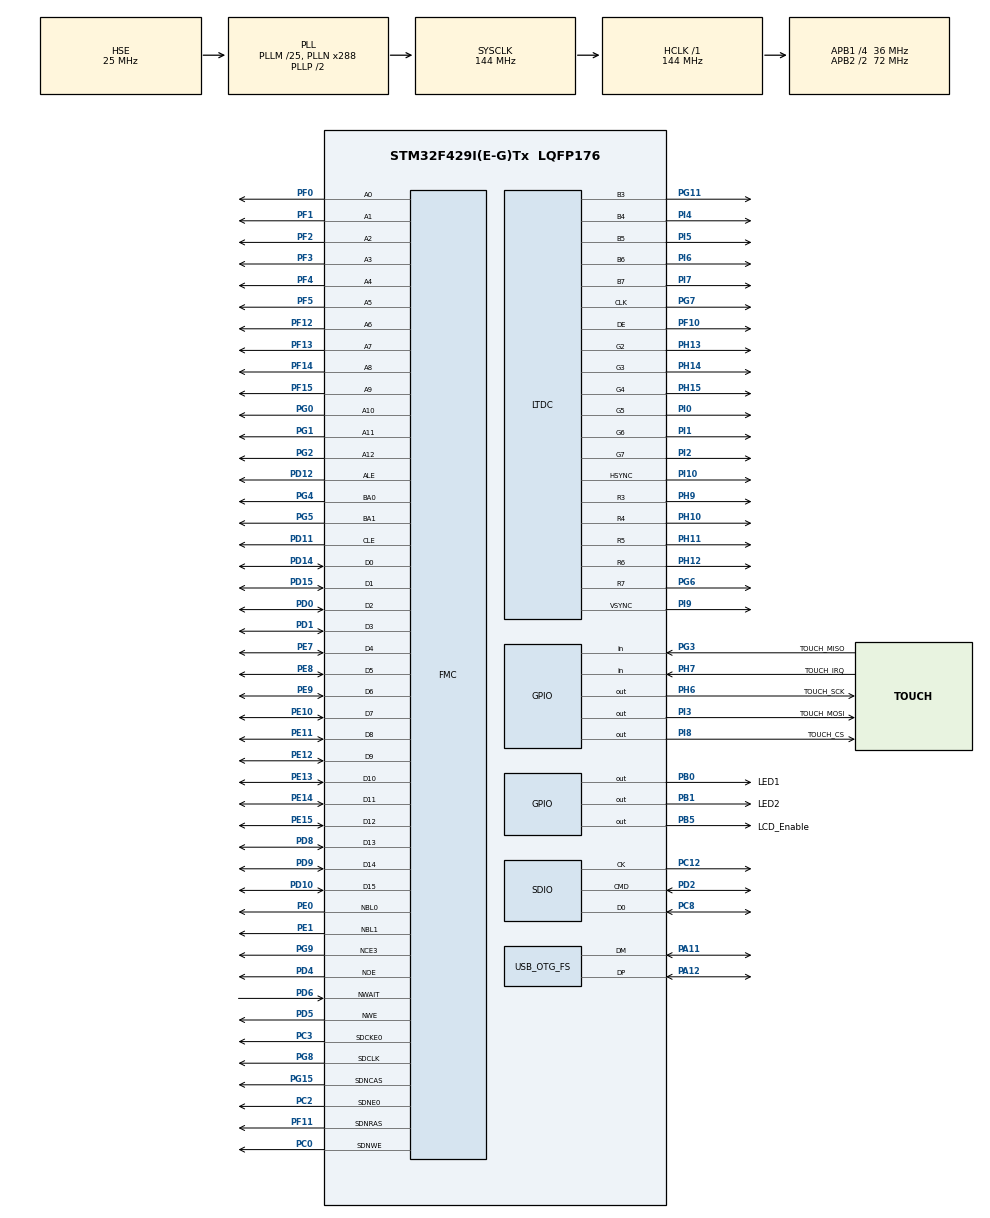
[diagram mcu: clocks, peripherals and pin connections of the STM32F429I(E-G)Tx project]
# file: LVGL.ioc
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DMA2D.ColorMode=DMA2D_OUTPUT_RGB565
FATFS._USE_LFN=2
FMC.AttributeSpaceHiZSetupTime1=252
FMC.AttributeSpaceHoldSetupTime1=10
FMC.AttributeSpaceSetupTime1=9
FMC.AttributeSpaceWaitSetupTime1=9
FMC.CASLatency1=FMC_SDRAM_CAS_LATENCY_2
FMC.ColumnBitsNumber1=FMC_SDRAM_COLUMN_BITS_NUM_9
FMC.CommonSpaceHiZSetupTime1=9
FMC.CommonSpaceHoldSetupTime1=10
FMC.CommonSpaceSetupTime1=9
FMC.CommonSpaceWaitSetupTime1=9
FMC.ExitSelfRefreshDelay1=7
FMC.LoadToActiveDelay1=2
FMC.NandBlockNbr1=2048
FMC.NandBlockSize1=64
FMC.NandPageSize1=2048
FMC.NandPlaneNbr1=2
FMC.NandPlaneSize1=1024
FMC.NandSpareAreaSize1=8
FMC.RCDDelay1=2
FMC.RPDelay1=2
FMC.RowCycleDelay1=7
FMC.SDClockPeriod1=FMC_SDRAM_CLOCK_PERIOD_2
FMC.SelfRefreshTime1=4
FMC.TARSetupTime1=1
FMC.TCLRSetupTime1=1
FMC.WriteRecoveryTime1=3
LTDC.ActiveW=800
LTDC.Alpha_L0=255
LTDC.FBStartAdress_L0=0xC0000000
LTDC.HBP=46
LTDC.HFP=210
LTDC.HSync=1
LTDC.ImageHeight_L0=480
LTDC.ImageWidth_L0=800
LTDC.Layers=0
LTDC.PixelFormat_L0=LTDC_PIXEL_FORMAT_RGB565
LTDC.VBP=23
LTDC.VFP=22
LTDC.VSync=1
LTDC.WindowX1_L0=800
LTDC.WindowY1_L0=480
Mcu.Family=STM32F4
Mcu.Name=STM32F429I(E-G)Tx
Mcu.Package=LQFP176
NVIC.DMA2D_IRQn=true\:0\:0\:false\:false\:true\:true\:true
NVIC.LTDC_IRQn=true\:0\:0\:false\:false\:true\:true\:true
NVIC.OTG_FS_IRQn=true\:0\:0\:false\:false\:true\:false\:true
NVIC.PriorityGroup=NVIC_PRIORITYGROUP_4
PA11.Mode=Device_Only
PA11.Signal=USB_OTG_FS_DM
PA12.Mode=Device_Only
PA12.Signal=USB_OTG_FS_DP
PA13.Mode=Serial_Wire
PA13.Signal=SYS_JTMS-SWDIO
PA14.Mode=Serial_Wire
PA14.Signal=SYS_JTCK-SWCLK
PB0.GPIO_Label=LED1
PB0.Signal=GPIO_Output
PB1.GPIO_Label=LED2
PB1.Signal=GPIO_Output
PB5.GPIO_Label=LCD_Enable
PB5.PinState=GPIO_PIN_SET
PB5.Signal=GPIO_Output
PC0.Signal=FMC_SDNWE
PC12.Mode=SD_1_bit
PC12.Signal=SDIO_CK
PC2.Mode=SdramChipSelect1_1
PC2.Signal=FMC_SDNE0
PC3.Mode=SdramChipSelect1_1
PC3.Signal=FMC_SDCKE0
PC8.Mode=SD_1_bit
PC8.Signal=SDIO_D0
PD0.Signal=FMC_D2_DA2
PD1.Signal=FMC_D3_DA3
PD10.Signal=FMC_D15_DA15
PD11.Signal=FMC_A16_CLE
PD12.Signal=FMC_A17_ALE
PD14.Signal=FMC_D0_DA0
PD15.Signal=FMC_D1_DA1
PD2.Mode=SD_1_bit
PD2.Signal=SDIO_CMD
PD4.Signal=FMC_NOE
PD5.Signal=FMC_NWE
PD6.Signal=FMC_NWAIT
PD8.Signal=FMC_D13_DA13
PD9.Signal=FMC_D14_DA14
PE0.Signal=FMC_NBL0
PE1.Signal=FMC_NBL1
PE10.Signal=FMC_D7_DA7
PE11.Signal=FMC_D8_DA8
PE12.Signal=FMC_D9_DA9
PE13.Signal=FMC_D10_DA10
PE14.Signal=FMC_D11_DA11
PE15.Signal=FMC_D12_DA12
PE7.Signal=FMC_D4_DA4
PE8.Signal=FMC_D5_DA5
PE9.Signal=FMC_D6_DA6
PF0.Signal=FMC_A0
PF1.Signal=FMC_A1
PF10.GPIO_Speed=GPIO_SPEED_FREQ_VERY_HIGH
PF10.Mode=RGB565
PF10.Signal=LTDC_DE
PF11.Signal=FMC_SDNRAS
PF12.Signal=FMC_A6
PF13.Signal=FMC_A7
PF14.Signal=FMC_A8
PF15.Signal=FMC_A9
PF2.Signal=FMC_A2
PF3.Signal=FMC_A3
PF4.Signal=FMC_A4
PF5.Signal=FMC_A5
PG0.Signal=FMC_A10
PG1.Signal=FMC_A11
PG11.GPIO_Speed=GPIO_SPEED_FREQ_VERY_HIGH
PG11.Mode=RGB565
PG11.Signal=LTDC_B3
PG15.Signal=FMC_SDNCAS
PG2.Signal=FMC_A12
PG3.GPIO_Label=TOUCH_MISO
PG3.Signal=GPIO_Input
PG4.Signal=FMC_A14_BA0
PG5.Signal=FMC_A15_BA1
PG6.GPIO_Speed=GPIO_SPEED_FREQ_VERY_HIGH
PG6.Mode=RGB565
PG6.Signal=LTDC_R7
PG7.GPIO_Speed=GPIO_SPEED_FREQ_VERY_HIGH
PG7.Mode=RGB565
PG7.Signal=LTDC_CLK
PG8.Signal=FMC_SDCLK
PG9.Mode=NandChipSelect3_1
PG9.Signal=FMC_NCE3
PH0/OSC_IN.Mode=HSE-External-Oscillator
PH0/OSC_IN.Signal=RCC_OSC_IN
PH1/OSC_OUT.Mode=HSE-External-Oscillator
PH1/OSC_OUT.Signal=RCC_OSC_OUT
PH10.GPIO_Speed=GPIO_SPEED_FREQ_VERY_HIGH
PH10.Mode=RGB565
PH10.Signal=LTDC_R4
PH11.GPIO_Speed=GPIO_SPEED_FREQ_VERY_HIGH
PH11.Mode=RGB565
PH11.Signal=LTDC_R5
PH12.GPIO_Speed=GPIO_SPEED_FREQ_VERY_HIGH
PH12.Mode=RGB565
PH12.Signal=LTDC_R6
PH13.GPIO_Speed=GPIO_SPEED_FREQ_VERY_HIGH
PH13.Mode=RGB565
PH13.Signal=LTDC_G2
PH14.GPIO_Speed=GPIO_SPEED_FREQ_VERY_HIGH
PH14.Mode=RGB565
PH14.Signal=LTDC_G3
PH15.GPIO_Speed=GPIO_SPEED_FREQ_VERY_HIGH
PH15.Mode=RGB565
PH15.Signal=LTDC_G4
PH6.GPIO_Label=TOUCH_SCK
PH6.Signal=GPIO_Output
PH7.GPIO_Label=TOUCH_IRQ
PH7.Signal=GPIO_Input
PH9.GPIO_Speed=GPIO_SPEED_FREQ_VERY_HIGH
PH9.Mode=RGB565
PH9.Signal=LTDC_R3
PI0.GPIO_Speed=GPIO_SPEED_FREQ_VERY_HIGH
PI0.Mode=RGB565
PI0.Signal=LTDC_G5
PI1.GPIO_Speed=GPIO_SPEED_FREQ_VERY_HIGH
PI1.Mode=RGB565
PI1.Signal=LTDC_G6
PI10.GPIO_Speed=GPIO_SPEED_FREQ_VERY_HIGH
PI10.Mode=RGB565
PI10.Signal=LTDC_HSYNC
PI2.GPIO_Speed=GPIO_SPEED_FREQ_VERY_HIGH
PI2.Mode=RGB565
PI2.Signal=LTDC_G7
PI3.GPIO_Label=TOUCH_MOSI
PI3.Signal=GPIO_Output
PI4.GPIO_Speed=GPIO_SPEED_FREQ_VERY_HIGH
PI4.Mode=RGB565
PI4.Signal=LTDC_B4
PI5.GPIO_Speed=GPIO_SPEED_FREQ_VERY_HIGH
PI5.Mode=RGB565
PI5.Signal=LTDC_B5
PI6.GPIO_Speed=GPIO_SPEED_FREQ_VERY_HIGH
PI6.Mode=RGB565
PI6.Signal=LTDC_B6
PI7.GPIO_Speed=GPIO_SPEED_FREQ_VERY_HIGH
PI7.Mode=RGB565
PI7.Signal=LTDC_B7
PI8.GPIO_Label=TOUCH_CS
PI8.Signal=GPIO_Output
PI9.GPIO_Speed=GPIO_SPEED_FREQ_VERY_HIGH
PI9.Mode=RGB565
PI9.Signal=LTDC_VSYNC
ProjectManager.HeapSize=0x2000
ProjectManager.StackSize=0x2000
ProjectManager.TargetToolchain=MDK-ARM V5.27
RCC.48MHZClocksFreq_Value=48000000
RCC.AHBFreq_Value=144000000
RCC.APB1CLKDivider=RCC_HCLK_DIV4
RCC.APB1Freq_Value=36000000
RCC.APB1TimFreq_Value=72000000
RCC.APB2CLKDivider=RCC_HCLK_DIV2
RCC.APB2Freq_Value=72000000
RCC.APB2TimFreq_Value=144000000
RCC.CortexFreq_Value=144000000
RCC.EnbaleCSS=true
RCC.HCLKFreq_Value=144000000
RCC.HSE_VALUE=25000000
RCC.HSI_VALUE=16000000
RCC.LSE_VALUE=32768
RCC.PLLM=25
RCC.PLLN=288
RCC.PLLQ=6
RCC.PLLSAIN=200
RCC.PLLSAIR=3
RCC.SYSCLKFreq_VALUE=144000000
RCC.SYSCLKSource=RCC_SYSCLKSOURCE_PLLCLK
RCC.VCOOutputFreq_Value=288000000
SH.FMC_A0.0=FMC_A0,13b-sda1
SH.FMC_A1.0=FMC_A1,13b-sda1
SH.FMC_A10.0=FMC_A10,13b-sda1
SH.FMC_A11.0=FMC_A11,13b-sda1
SH.FMC_A12.0=FMC_A12,13b-sda1
SH.FMC_A14_BA0.0=FMC_BA0,FourSdramBanks1
SH.FMC_A15_BA1.0=FMC_BA1,FourSdramBanks1
SH.FMC_A16_CLE.0=FMC_CLE,8b-dmux1
SH.FMC_A17_ALE.0=FMC_ALE,8b-dmux1
SH.FMC_A2.0=FMC_A2,13b-sda1
SH.FMC_A3.0=FMC_A3,13b-sda1
SH.FMC_A4.0=FMC_A4,13b-sda1
SH.FMC_A5.0=FMC_A5,13b-sda1
SH.FMC_A6.0=FMC_A6,13b-sda1
SH.FMC_A7.0=FMC_A7,13b-sda1
SH.FMC_A8.0=FMC_A8,13b-sda1
SH.FMC_A9.0=FMC_A9,13b-sda1
SH.FMC_D0_DA0.0=FMC_D0,sd-16b-d1
SH.FMC_D0_DA0.1=FMC_D0,8b-dmux1
SH.FMC_D10_DA10.0=FMC_D10,sd-16b-d1
SH.FMC_D11_DA11.0=FMC_D11,sd-16b-d1
SH.FMC_D12_DA12.0=FMC_D12,sd-16b-d1
SH.FMC_D13_DA13.0=FMC_D13,sd-16b-d1
SH.FMC_D14_DA14.0=FMC_D14,sd-16b-d1
SH.FMC_D15_DA15.0=FMC_D15,sd-16b-d1
SH.FMC_D1_DA1.0=FMC_D1,sd-16b-d1
SH.FMC_D1_DA1.1=FMC_D1,8b-dmux1
SH.FMC_D2_DA2.0=FMC_D2,sd-16b-d1
SH.FMC_D2_DA2.1=FMC_D2,8b-dmux1
SH.FMC_D3_DA3.0=FMC_D3,sd-16b-d1
SH.FMC_D3_DA3.1=FMC_D3,8b-dmux1
SH.FMC_D4_DA4.0=FMC_D4,sd-16b-d1
SH.FMC_D4_DA4.1=FMC_D4,8b-dmux1
SH.FMC_D5_DA5.0=FMC_D5,sd-16b-d1
SH.FMC_D5_DA5.1=FMC_D5,8b-dmux1
SH.FMC_D6_DA6.0=FMC_D6,sd-16b-d1
SH.FMC_D6_DA6.1=FMC_D6,8b-dmux1
SH.FMC_D7_DA7.0=FMC_D7,sd-16b-d1
SH.FMC_D7_DA7.1=FMC_D7,8b-dmux1
SH.FMC_D8_DA8.0=FMC_D8,sd-16b-d1
SH.FMC_D9_DA9.0=FMC_D9,sd-16b-d1
SH.FMC_NBL0.0=FMC_NBL0,Sd2ByteEnable1
SH.FMC_NBL1.0=FMC_NBL1,Sd2ByteEnable1
SH.FMC_NOE.0=FMC_NOE,8b-dmux1
SH.FMC_NWAIT.0=FMC_NWAIT,Wait1
SH.FMC_NWE.0=FMC_NWE,8b-dmux1
SH.FMC_SDCLK.0=FMC_SDCLK,13b-sda1
SH.FMC_SDNCAS.0=FMC_SDNCAS,13b-sda1
SH.FMC_SDNRAS.0=FMC_SDNRAS,13b-sda1
SH.FMC_SDNWE.0=FMC_SDNWE,13b-sda1
USB_DEVICE.CLASS_NAME_FS=CDC
USB_DEVICE.VirtualMode-CDC_FS=Cdc
USB_DEVICE.VirtualModeFS=Cdc_FS
USB_OTG_FS.VirtualMode=Device_Only
VP_CRC_VS_CRC.Mode=CRC_Activate
VP_DMA2D_VS_DMA2D.Mode=DMA2D_Activate
VP_FATFS_VS_SDIO.Mode=SDIO
VP_USB_DEVICE_VS_USB_DEVICE_CDC_FS.Mode=CDC_FS
board=custom

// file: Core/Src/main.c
/* USER CODE BEGIN Header */
/**
  ******************************************************************************
  * @file           : main.c
  * @brief          : Main program body
  ******************************************************************************
  * @attention
  *
  * <h2><center>&copy; Copyright (c) 2020 STMicroelectronics.
  * All rights reserved.</center></h2>
  *
  * This software component is licensed by ST under Ultimate Liberty license
  * SLA0044, the "License"; You may not use this file except in compliance with
  * the License. You may obtain a copy of the License at:
  *                             www.st.com/SLA0044
  *
  ******************************************************************************
  */
/* USER CODE END Header */
#include "main.h"
#include "fatfs.h"
#include "usb_device.h"

/* USER CODE BEGIN Includes */
#include "usbd_cdc_if.h"
#include "../../lvgl/lvgl.h"
#include "../../lvgl/src/lv_init.h"
#include "../../lvgl/examples/lv_examples.h"

/* USER CODE END Includes */

/* USER CODE BEGIN PD */
#define WRITE_READ_ADDR   ((uint16_t*)0xC0000000)
#define SDRAM_MODEREG_BURST_LENGTH_1             ((uint16_t)0x0000)
#define SDRAM_MODEREG_BURST_LENGTH_2             ((uint16_t)0x0001)
#define SDRAM_MODEREG_BURST_LENGTH_4             ((uint16_t)0x0002)
#define SDRAM_MODEREG_BURST_LENGTH_8             ((uint16_t)0x0004)
#define SDRAM_MODEREG_BURST_TYPE_SEQUENTIAL      ((uint16_t)0x0000)
#define SDRAM_MODEREG_BURST_TYPE_INTERLEAVED     ((uint16_t)0x0008)
#define SDRAM_MODEREG_CAS_LATENCY_2              ((uint16_t)0x0020)
#define SDRAM_MODEREG_CAS_LATENCY_3              ((uint16_t)0x0030)
#define SDRAM_MODEREG_OPERATING_MODE_STANDARD    ((uint16_t)0x0000)
#define SDRAM_MODEREG_WRITEBURST_MODE_PROGRAMMED ((uint16_t)0x0000)
#define SDRAM_MODEREG_WRITEBURST_MODE_SINGLE     ((uint16_t)0x0200)
#define REFRESH_COUNT       ((uint32_t)1835)   /* SDRAM refresh counter (90MHz SD clock) */

#define LV_HOR_RES_MAX 800
#define LV_VER_RES_MAX 400

/* USER CODE END PD */

CRC_HandleTypeDef hcrc;

DMA2D_HandleTypeDef hdma2d;

LTDC_HandleTypeDef hltdc;

SD_HandleTypeDef hsd;

NAND_HandleTypeDef hnand1;
SDRAM_HandleTypeDef hsdram1;

/* USER CODE BEGIN PV */
/*A static or global variable to store the buffers*/
//lv_disp_t * disp;
//static lv_disp_buf_t disp_buf;
//static lv_disp_drv_t disp_drv;
//
///*Static or global buffer(s). The second buffer is optional*/
//static lv_color_t buf_1[LV_HOR_RES_MAX * 10];
//static lv_color_t buf_2[LV_HOR_RES_MAX * 10];

static uint16_t buf[LV_HOR_RES_MAX * LV_VER_RES_MAX / 10];

uint16_t* LCD_FB=(uint16_t*)0xC0000000; // LCD FRAME Buffer
NAND_AddressTypeDef NAND_Address;
static volatile uint32_t t_saved = 0;
/* USER CODE END PV */

void SystemClock_Config(void);
static void MX_GPIO_Init(void);
static void MX_LTDC_Init(void);
static void MX_FMC_Init(void);
static void MX_SDIO_SD_Init(void);
static void MX_DMA2D_Init(void);
static void MX_CRC_Init(void);
///* USER CODE BEGIN PFP */
//void lcd_flush_cb(lv_disp_drv_t * disp_drv, const lv_area_t * area, lv_color_t * color_p);
//void my_gpu_fill_cb(lv_disp_drv_t * disp_drv, lv_color_t * dest_buf, const lv_area_t * dest_area, const lv_area_t * fill_area, lv_color_t color);
void SDRAM_Initialization_Sequence(SDRAM_HandleTypeDef *hsdram, FMC_SDRAM_CommandTypeDef *Command);
//void monitor_cb(lv_disp_drv_t * d, uint32_t t, uint32_t p);
//static void tft_lcd_flush_cb(lv_disp_drv_t * drv, const lv_area_t * area, lv_color_t * color_p) ;

/* USER CODE END PFP */

/* USER CODE BEGIN 0 */

void HAL_SYSTICK_Callback(void)
{

}

void put_px(int32_t x, int32_t y, uint16_t color) {
    // This is a placeholder implementation. Replace it with your actual implementation
    // Write the pixel color to the display buffer at the specified coordinates
	buf[y * LV_HOR_RES_MAX + x] = lv_color_to_u32(lv_color_make((color >> 11) & 0x1F, (color >> 5) & 0x3F, color & 0x1F));
}

void my_flush_cb(lv_display_t * display, const lv_area_t * area, void * px_map)
{
    /*The most simple case (but also the slowest) to put all pixels to the screen one-by-one
     *`put_px` is just an example, it needs to be implemented by you.*/
    uint16_t * buf16 = (uint16_t *)px_map; /*Let's say it's a 16 bit (RGB565) display*/
    int32_t x, y;
    for(y = area->y1; y <= area->y2; y++) {
        for(x = area->x1; x <= area->x2; x++) {
            put_px(x, y, *buf16);
            buf16++;
        }
    }

    /* IMPORTANT!!!
     * Inform LVGL that you are ready with the flushing and buf is not used anymore*/
    lv_display_flush_ready(display);
}
//
//void my_flush_cb(lv_display_t * display, const lv_area_t *area, lv_color_t *color_p) {
//    // Handle the spinner (if needed)
//    // For example, update the spinner's animation here
//    // Draw other display content (similar to the previous implementation)
//    int32_t x, y;
//    for (y = area->y1; y <= area->y2; y++) {
//        for (x = area->x1; x <= area->x2; x++) {
//            // Replace the following line with your actual display driver function
//            // to set the pixel at coordinates (x, y) with the specified color
//            put_px(x, y, *color_p);
//            color_p++;
//        }
//    }
//
//}

/* USER CODE END 0 */

int main(void)
{
  /* USER CODE BEGIN 1 */
//	NAND_IDTypeDef NAND1_ID;
//	char buff[50],buff_len;
  /* USER CODE END 1 */

  /* MCU Configuration--------------------------------------------------------*/

  /* Reset of all peripherals, Initializes the Flash interface and the Systick. */
  HAL_Init();

  /* Configure the system clock */
  SystemClock_Config();

  /* Initialize all configured peripherals */
  MX_GPIO_Init();
  MX_LTDC_Init();
  MX_FMC_Init();
  MX_SDIO_SD_Init();
  MX_FATFS_Init();
  MX_DMA2D_Init();
  MX_CRC_Init();
  MX_USB_DEVICE_Init();
  /* USER CODE BEGIN 2 */
//  for (unsigned int l_ind=0; l_ind<=384000; l_ind++)
//	LCD_FB[l_ind]=0x0000;
//  HAL_Delay(2000);
//	HAL_NAND_Erase_Block(&hnand1,&NAND_Address);
//  HAL_NAND_Write_Page_8b(&hnand1,&NAND_Address,(uint8_t *)"21AH\n\r",1);
//  HAL_NAND_Read_ID(&hnand1,&NAND1_ID);
//  buff_len=sprintf(buff,"%d,%d,%d,%d\n\r",NAND1_ID.Device_Id,NAND1_ID.Maker_Id,NAND1_ID.Third_Id,NAND1_ID.Fourth_Id);
//  HAL_Delay(2000);
//  CDC_Transmit_FS((uint8_t*)buff,buff_len);
//	//	HAL_NAND_Read_Page_8b(&hnand1,&NAND_Address,(uint8_t *)buff2,1);
//  for (unsigned int l_ind=0; l_ind<=384000; l_ind++)
//	LCD_FB[l_ind]=0xDCBA;
//	/*Initialize `disp_buf` with the buffer(s) */
//  HAL_Delay(100);
  lv_init();
  /*Initialize `disp_buf` with the buffer(s) */
  lv_display_t *display = lv_display_create(LV_HOR_RES_MAX, LV_VER_RES_MAX);
  lv_display_set_buffers(display, buf, NULL, sizeof(buf),LV_DISPLAY_RENDER_MODE_PARTIAL);
  lv_display_set_flush_cb(display, my_flush_cb);

  lv_obj_t *parent = lv_obj_create(lv_scr_act());
  lv_obj_set_size(parent, 100, 80);
  lv_obj_set_style_bg_color(parent, lv_color_hex(0x003a57), LV_PART_MAIN);

  lv_obj_t *spinner = lv_spinner_create(parent);
  lv_spinner_set_anim_params(spinner, 1000, 45); // Customize spin duration and arc length
  lv_obj_align(spinner, LV_ALIGN_BOTTOM_MID, 0, 0);

//  lv_area_t rect_area = {10, 10, 50, 30};
//  uint16_t rect_color = 0xF800; // Red (RGB565)
//  draw_filled_rectangle(display, &rect_area, rect_color);

  /* USER CODE END 2 */

  /* Infinite loop */
  /* USER CODE BEGIN WHILE */
  while (1)
  {
	  HAL_Delay(10);
	  lv_tick_inc(10);
	  lv_task_handler();
    /* USER CODE END WHILE */

  }
}

void SystemClock_Config(void)
{
  RCC_OscInitTypeDef RCC_OscInitStruct = {0};
  RCC_ClkInitTypeDef RCC_ClkInitStruct = {0};
  RCC_PeriphCLKInitTypeDef PeriphClkInitStruct = {0};

  /** Configure the main internal regulator output voltage
  */
  __HAL_RCC_PWR_CLK_ENABLE();
  __HAL_PWR_VOLTAGESCALING_CONFIG(PWR_REGULATOR_VOLTAGE_SCALE1);
  /** Initializes the RCC Oscillators according to the specified parameters
  * in the RCC_OscInitTypeDef structure.
  */
  RCC_OscInitStruct.OscillatorType = RCC_OSCILLATORTYPE_HSE;
  RCC_OscInitStruct.HSEState = RCC_HSE_ON;
  RCC_OscInitStruct.PLL.PLLState = RCC_PLL_ON;
  RCC_OscInitStruct.PLL.PLLSource = RCC_PLLSOURCE_HSE;
  RCC_OscInitStruct.PLL.PLLM = 25;
  RCC_OscInitStruct.PLL.PLLN = 288;
  RCC_OscInitStruct.PLL.PLLP = RCC_PLLP_DIV2;
  RCC_OscInitStruct.PLL.PLLQ = 6;
  if (HAL_RCC_OscConfig(&RCC_OscInitStruct) != HAL_OK)
  {
    Error_Handler();
  }
  /** Initializes the CPU, AHB and APB buses clocks
  */
  RCC_ClkInitStruct.ClockType = RCC_CLOCKTYPE_HCLK|RCC_CLOCKTYPE_SYSCLK
                              |RCC_CLOCKTYPE_PCLK1|RCC_CLOCKTYPE_PCLK2;
  RCC_ClkInitStruct.SYSCLKSource = RCC_SYSCLKSOURCE_PLLCLK;
  RCC_ClkInitStruct.AHBCLKDivider = RCC_SYSCLK_DIV1;
  RCC_ClkInitStruct.APB1CLKDivider = RCC_HCLK_DIV4;
  RCC_ClkInitStruct.APB2CLKDivider = RCC_HCLK_DIV2;

  if (HAL_RCC_ClockConfig(&RCC_ClkInitStruct, FLASH_LATENCY_4) != HAL_OK)
  {
    Error_Handler();
  }
  PeriphClkInitStruct.PeriphClockSelection = RCC_PERIPHCLK_LTDC;
  PeriphClkInitStruct.PLLSAI.PLLSAIN = 200;
  PeriphClkInitStruct.PLLSAI.PLLSAIR = 3;
  PeriphClkInitStruct.PLLSAIDivR = RCC_PLLSAIDIVR_2;
  if (HAL_RCCEx_PeriphCLKConfig(&PeriphClkInitStruct) != HAL_OK)
  {
    Error_Handler();
  }
  /** Enables the Clock Security System
  */
  HAL_RCC_EnableCSS();
}

///**
//  * @brief CRC Initialization Function
//  * @param None
//  * @retval None
//  */
static void MX_CRC_Init(void)
{

  hcrc.Instance = CRC;
  if (HAL_CRC_Init(&hcrc) != HAL_OK)
  {
    Error_Handler();
  }

}

static void MX_DMA2D_Init(void)
{

  hdma2d.Instance = DMA2D;
  hdma2d.Init.Mode = DMA2D_M2M;
  hdma2d.Init.ColorMode = DMA2D_OUTPUT_RGB565;
  hdma2d.Init.OutputOffset = 0;
  hdma2d.LayerCfg[1].InputOffset = 0;
  hdma2d.LayerCfg[1].InputColorMode = DMA2D_INPUT_RGB565;
  hdma2d.LayerCfg[1].AlphaMode = DMA2D_NO_MODIF_ALPHA;
  hdma2d.LayerCfg[1].InputAlpha = 0;
  if (HAL_DMA2D_Init(&hdma2d) != HAL_OK)
  {
    Error_Handler();
  }
  if (HAL_DMA2D_ConfigLayer(&hdma2d, 1) != HAL_OK)
  {
    Error_Handler();
  }

}

///**
//  * @brief LTDC Initialization Function
//  * @param None
//  * @retval None
//  */
static void MX_LTDC_Init(void)
{

  LTDC_LayerCfgTypeDef pLayerCfg = {0};
  LTDC_LayerCfgTypeDef pLayerCfg1 = {0};

  hltdc.Instance = LTDC;
  hltdc.Init.HSPolarity = LTDC_HSPOLARITY_AL;
  hltdc.Init.VSPolarity = LTDC_VSPOLARITY_AL;
  hltdc.Init.DEPolarity = LTDC_DEPOLARITY_AL;
  hltdc.Init.PCPolarity = LTDC_PCPOLARITY_IPC;
  hltdc.Init.HorizontalSync = 0;
  hltdc.Init.VerticalSync = 0;
  hltdc.Init.AccumulatedHBP = 46;
  hltdc.Init.AccumulatedVBP = 23;
  hltdc.Init.AccumulatedActiveW = 846;
  hltdc.Init.AccumulatedActiveH = 503;
  hltdc.Init.TotalWidth = 1056;
  hltdc.Init.TotalHeigh = 525;
  hltdc.Init.Backcolor.Blue = 0;
  hltdc.Init.Backcolor.Green = 0;
  hltdc.Init.Backcolor.Red = 0;
  if (HAL_LTDC_Init(&hltdc) != HAL_OK)
  {
    Error_Handler();
  }
  pLayerCfg.WindowX0 = 0;
  pLayerCfg.WindowX1 = 800;
  pLayerCfg.WindowY0 = 0;
  pLayerCfg.WindowY1 = 480;
  pLayerCfg.PixelFormat = LTDC_PIXEL_FORMAT_RGB565;
  pLayerCfg.Alpha = 255;
  pLayerCfg.Alpha0 = 0;
  pLayerCfg.BlendingFactor1 = LTDC_BLENDING_FACTOR1_CA;
  pLayerCfg.BlendingFactor2 = LTDC_BLENDING_FACTOR2_CA;
  pLayerCfg.FBStartAdress = 0xC0000000;
  pLayerCfg.ImageWidth = 800;
  pLayerCfg.ImageHeight = 480;
  pLayerCfg.Backcolor.Blue = 0;
  pLayerCfg.Backcolor.Green = 0;
  pLayerCfg.Backcolor.Red = 0;
  if (HAL_LTDC_ConfigLayer(&hltdc, &pLayerCfg, 0) != HAL_OK)
  {
    Error_Handler();
  }
  pLayerCfg1.WindowX0 = 0;
  pLayerCfg1.WindowX1 = 0;
  pLayerCfg1.WindowY0 = 0;
  pLayerCfg1.WindowY1 = 0;
  pLayerCfg1.Alpha = 0;
  pLayerCfg1.Alpha0 = 0;
  pLayerCfg1.BlendingFactor1 = LTDC_BLENDING_FACTOR1_CA;
  pLayerCfg1.BlendingFactor2 = LTDC_BLENDING_FACTOR2_CA;
  pLayerCfg1.FBStartAdress = 0;
  pLayerCfg1.ImageWidth = 0;
  pLayerCfg1.ImageHeight = 0;
  pLayerCfg1.Backcolor.Blue = 0;
  pLayerCfg1.Backcolor.Green = 0;
  pLayerCfg1.Backcolor.Red = 0;
  if (HAL_LTDC_ConfigLayer(&hltdc, &pLayerCfg1, 1) != HAL_OK)
  {
    Error_Handler();
  }

}

///**
//  * @brief SDIO Initialization Function
//  * @param None
//  * @retval None
//  */
static void MX_SDIO_SD_Init(void)
{

  hsd.Instance = SDIO;
  hsd.Init.ClockEdge = SDIO_CLOCK_EDGE_RISING;
  hsd.Init.ClockBypass = SDIO_CLOCK_BYPASS_DISABLE;
  hsd.Init.ClockPowerSave = SDIO_CLOCK_POWER_SAVE_DISABLE;
  hsd.Init.BusWide = SDIO_BUS_WIDE_1B;
  hsd.Init.HardwareFlowControl = SDIO_HARDWARE_FLOW_CONTROL_DISABLE;
  hsd.Init.ClockDiv = 0;

}

/* FMC initialization function */
static void MX_FMC_Init(void)
{

  FMC_NAND_PCC_TimingTypeDef ComSpaceTiming = {0};
  FMC_NAND_PCC_TimingTypeDef AttSpaceTiming = {0};
  FMC_SDRAM_TimingTypeDef SdramTiming = {0};

  /** Perform the NAND1 memory initialization sequence
  */
  hnand1.Instance = FMC_NAND_DEVICE;
  /* hnand1.Init */
  hnand1.Init.NandBank = FMC_NAND_BANK3;
  hnand1.Init.Waitfeature = FMC_NAND_PCC_WAIT_FEATURE_ENABLE;
  hnand1.Init.MemoryDataWidth = FMC_NAND_PCC_MEM_BUS_WIDTH_8;
  hnand1.Init.EccComputation = FMC_NAND_ECC_DISABLE;
  hnand1.Init.ECCPageSize = FMC_NAND_ECC_PAGE_SIZE_256BYTE;
  hnand1.Init.TCLRSetupTime = 1;
  hnand1.Init.TARSetupTime = 1;
  /* hnand1.Config */
  hnand1.Config.PageSize = 2048;
  hnand1.Config.SpareAreaSize = 8;
  hnand1.Config.BlockSize = 64;
  hnand1.Config.BlockNbr = 2048;
  hnand1.Config.PlaneNbr = 2;
  hnand1.Config.PlaneSize = 1024;
  hnand1.Config.ExtraCommandEnable = DISABLE;
  /* ComSpaceTiming */
  ComSpaceTiming.SetupTime = 9;
  ComSpaceTiming.WaitSetupTime = 9;
  ComSpaceTiming.HoldSetupTime = 10;
  ComSpaceTiming.HiZSetupTime = 9;
  /* AttSpaceTiming */
  AttSpaceTiming.SetupTime = 9;
  AttSpaceTiming.WaitSetupTime = 9;
  AttSpaceTiming.HoldSetupTime = 10;
  AttSpaceTiming.HiZSetupTime = 252;

  if (HAL_NAND_Init(&hnand1, &ComSpaceTiming, &AttSpaceTiming) != HAL_OK)
  {
    Error_Handler( );
  }

  /** Perform the SDRAM1 memory initialization sequence
  */
  hsdram1.Instance = FMC_SDRAM_DEVICE;
  /* hsdram1.Init */
  hsdram1.Init.SDBank = FMC_SDRAM_BANK1;
  hsdram1.Init.ColumnBitsNumber = FMC_SDRAM_COLUMN_BITS_NUM_9;
  hsdram1.Init.RowBitsNumber = FMC_SDRAM_ROW_BITS_NUM_13;
  hsdram1.Init.MemoryDataWidth = FMC_SDRAM_MEM_BUS_WIDTH_16;
  hsdram1.Init.InternalBankNumber = FMC_SDRAM_INTERN_BANKS_NUM_4;
  hsdram1.Init.CASLatency = FMC_SDRAM_CAS_LATENCY_2;
  hsdram1.Init.WriteProtection = FMC_SDRAM_WRITE_PROTECTION_DISABLE;
  hsdram1.Init.SDClockPeriod = FMC_SDRAM_CLOCK_PERIOD_2;
  hsdram1.Init.ReadBurst = FMC_SDRAM_RBURST_DISABLE;
  hsdram1.Init.ReadPipeDelay = FMC_SDRAM_RPIPE_DELAY_0;
  /* SdramTiming */
  SdramTiming.LoadToActiveDelay = 2;
  SdramTiming.ExitSelfRefreshDelay = 7;
  SdramTiming.SelfRefreshTime = 4;
  SdramTiming.RowCycleDelay = 7;
  SdramTiming.WriteRecoveryTime = 3;
  SdramTiming.RPDelay = 2;
  SdramTiming.RCDDelay = 2;

  if (HAL_SDRAM_Init(&hsdram1, &SdramTiming) != HAL_OK)
  {
    Error_Handler( );
  }

  /* USER CODE BEGIN FMC_Init 2 */
    FMC_SDRAM_CommandTypeDef SDRAM_Command;
    SDRAM_Initialization_Sequence(&hsdram1, &SDRAM_Command);
  /* USER CODE END FMC_Init 2 */
}

static void MX_GPIO_Init(void)
{
  GPIO_InitTypeDef GPIO_InitStruct = {0};

  /* GPIO Ports Clock Enable */
  __HAL_RCC_GPIOI_CLK_ENABLE();
  __HAL_RCC_GPIOF_CLK_ENABLE();
  __HAL_RCC_GPIOH_CLK_ENABLE();
  __HAL_RCC_GPIOC_CLK_ENABLE();
  __HAL_RCC_GPIOB_CLK_ENABLE();
  __HAL_RCC_GPIOG_CLK_ENABLE();
  __HAL_RCC_GPIOE_CLK_ENABLE();
  __HAL_RCC_GPIOD_CLK_ENABLE();
  __HAL_RCC_GPIOA_CLK_ENABLE();

  /*Configure GPIO pin Output Level */
  HAL_GPIO_WritePin(GPIOI, TOUCH_CS_Pin|TOUCH_MOSI_Pin, GPIO_PIN_RESET);

  /*Configure GPIO pin Output Level */
  HAL_GPIO_WritePin(GPIOB, LED1_Pin|LED2_Pin, GPIO_PIN_RESET);

  /*Configure GPIO pin Output Level */
  HAL_GPIO_WritePin(TOUCH_SCK_GPIO_Port, TOUCH_SCK_Pin, GPIO_PIN_RESET);

  /*Configure GPIO pin Output Level */
  HAL_GPIO_WritePin(LCD_Enable_GPIO_Port, LCD_Enable_Pin, GPIO_PIN_SET);

  /*Configure GPIO pins : TOUCH_CS_Pin TOUCH_MOSI_Pin */
  GPIO_InitStruct.Pin = TOUCH_CS_Pin|TOUCH_MOSI_Pin;
  GPIO_InitStruct.Mode = GPIO_MODE_OUTPUT_PP;
  GPIO_InitStruct.Pull = GPIO_NOPULL;
  GPIO_InitStruct.Speed = GPIO_SPEED_FREQ_LOW;
  HAL_GPIO_Init(GPIOI, &GPIO_InitStruct);

  /*Configure GPIO pins : LED1_Pin LED2_Pin LCD_Enable_Pin */
  GPIO_InitStruct.Pin = LED1_Pin|LED2_Pin|LCD_Enable_Pin;
  GPIO_InitStruct.Mode = GPIO_MODE_OUTPUT_PP;
  GPIO_InitStruct.Pull = GPIO_NOPULL;
  GPIO_InitStruct.Speed = GPIO_SPEED_FREQ_LOW;
  HAL_GPIO_Init(GPIOB, &GPIO_InitStruct);

  /*Configure GPIO pin : TOUCH_SCK_Pin */
  GPIO_InitStruct.Pin = TOUCH_SCK_Pin;
  GPIO_InitStruct.Mode = GPIO_MODE_OUTPUT_PP;
  GPIO_InitStruct.Pull = GPIO_NOPULL;
  GPIO_InitStruct.Speed = GPIO_SPEED_FREQ_LOW;
  HAL_GPIO_Init(TOUCH_SCK_GPIO_Port, &GPIO_InitStruct);

  /*Configure GPIO pin : TOUCH_IRQ_Pin */
  GPIO_InitStruct.Pin = TOUCH_IRQ_Pin;
  GPIO_InitStruct.Mode = GPIO_MODE_INPUT;
  GPIO_InitStruct.Pull = GPIO_NOPULL;
  HAL_GPIO_Init(TOUCH_IRQ_GPIO_Port, &GPIO_InitStruct);

  /*Configure GPIO pin : TOUCH_MISO_Pin */
  GPIO_InitStruct.Pin = TOUCH_MISO_Pin;
  GPIO_InitStruct.Mode = GPIO_MODE_INPUT;
  GPIO_InitStruct.Pull = GPIO_NOPULL;
  HAL_GPIO_Init(TOUCH_MISO_GPIO_Port, &GPIO_InitStruct);

}

///* USER CODE BEGIN 4 */
//void lcd_flush_cb(lv_disp_drv_t * disp_drv_int, const lv_area_t * area, lv_color_t * color_p)
//{
//    /*The most simple case (but also the slowest) to put all pixels to the screen one-by-one*/
//    int32_t x, y;
//    for(y = area->y1; y <= area->y2; y++) {
//        for(x = area->x1; x <= area->x2; x++) {
//			LCD_FB[x+(y * LV_HOR_RES_MAX)]=(color_p++->full);  //pixelColor;
//        }
//    }

//    /* IMPORTANT!!!
//     * Inform the graphics library that you are ready with the flushing*/
//    lv_disp_flush_ready(disp_drv_int);
//}
//void my_gpu_fill_cb(lv_disp_drv_t * disp_drv, lv_color_t * dest_buf, const lv_area_t * dest_area, const lv_area_t * fill_area, lv_color_t color)
//{
//    /*It's an example code which should be done by your GPU*/
//    uint32_t x, y;
//    dest_buf += LV_HOR_RES_MAX * fill_area->y1; /*Go to the first line*/

//    for(y = fill_area->y1; y < fill_area->y2; y++) {
//        for(x = fill_area->x1; x < fill_area->x2; x++) {
//            dest_buf[x] = color;
//        }
//        dest_buf+=LV_HOR_RES_MAX;    /*Go to the next line*/
//    }
//}
void SDRAM_Initialization_Sequence(SDRAM_HandleTypeDef *hsdram, FMC_SDRAM_CommandTypeDef *Command)
{
  /* Step 3:  Configure a clock configuration enable command */
  Command->CommandMode 			 = FMC_SDRAM_CMD_CLK_ENABLE;
  Command->CommandTarget 		 = FMC_SDRAM_CMD_TARGET_BANK1;
  Command->AutoRefreshNumber 	 = 1;
  Command->ModeRegisterDefinition = 0;

  /* Send the command */
  HAL_SDRAM_SendCommand(hsdram, Command, 0x1000);

  /* Step 4: Insert 100 ms delay */
  HAL_Delay(100);

  /* Step 5: Configure a PALL (precharge all) command */
  Command->CommandMode 			 = FMC_SDRAM_CMD_PALL;
  Command->CommandTarget 	     = FMC_SDRAM_CMD_TARGET_BANK1;
  Command->AutoRefreshNumber 	 = 1;
  Command->ModeRegisterDefinition = 0;

  /* Send the command */
  HAL_SDRAM_SendCommand(hsdram, Command, 0x1000);

  /* Step 6 : Configure a Auto-Refresh command */
  Command->CommandMode 			 = FMC_SDRAM_CMD_AUTOREFRESH_MODE;
  Command->CommandTarget 		 = FMC_SDRAM_CMD_TARGET_BANK1;
  Command->AutoRefreshNumber 	 = 8;
  Command->ModeRegisterDefinition = 0;

  /* Send the command */
  HAL_SDRAM_SendCommand(hsdram, Command, 0x1000);

  Command->CommandMode = FMC_SDRAM_CMD_LOAD_MODE;
  Command->CommandTarget 		 = FMC_SDRAM_CMD_TARGET_BANK1;
  Command->AutoRefreshNumber 	 = 1;
  Command->ModeRegisterDefinition = 0x0220;

  /* Send the command */
  HAL_SDRAM_SendCommand(hsdram, Command, 0x1000);

  /* Step 8: Set the refresh rate counter */
  /* (15.62 us x Freq) - 20 */
  /* Set the device refresh counter */
  HAL_SDRAM_ProgramRefreshRate(hsdram, REFRESH_COUNT);
}
//void monitor_cb(lv_disp_drv_t * d, uint32_t t, uint32_t p)
//{
//	t_saved = t;
//}
//static void tft_lcd_flush_cb(lv_disp_drv_t * drv, const lv_area_t * area, lv_color_t * color_p)
//	{
//	int16_t x1, y1,x2,y2;
//	x1=area->x1;
//	x2=area->x2;
//	y1=area->y1;
//	y2=area->y2;
//	if (x2>799)
//		x2=799;
//	if (y2>479)
//		y2=479;
//	if (y1<0)
//		y1=0;
//	if (y2<0)
//		y2=0;
//	if (x1<0)
//		x1=0;
//	if (x2<0)
//		x2=0;
//	for(int y = y1; y <= y2; y++)
//		for(int x = x1; x <= x2; x++)
//			LCD_FB[x+(y * LV_HOR_RES_MAX)]=(color_p++->full);  //pixelColor;
//
//	lv_disp_flush_ready(drv);
//}
/* USER CODE END 4 */

void Error_Handler(void)
{
}

/************************ (C) COPYRIGHT STMicroelectronics *****END OF FILE****/
